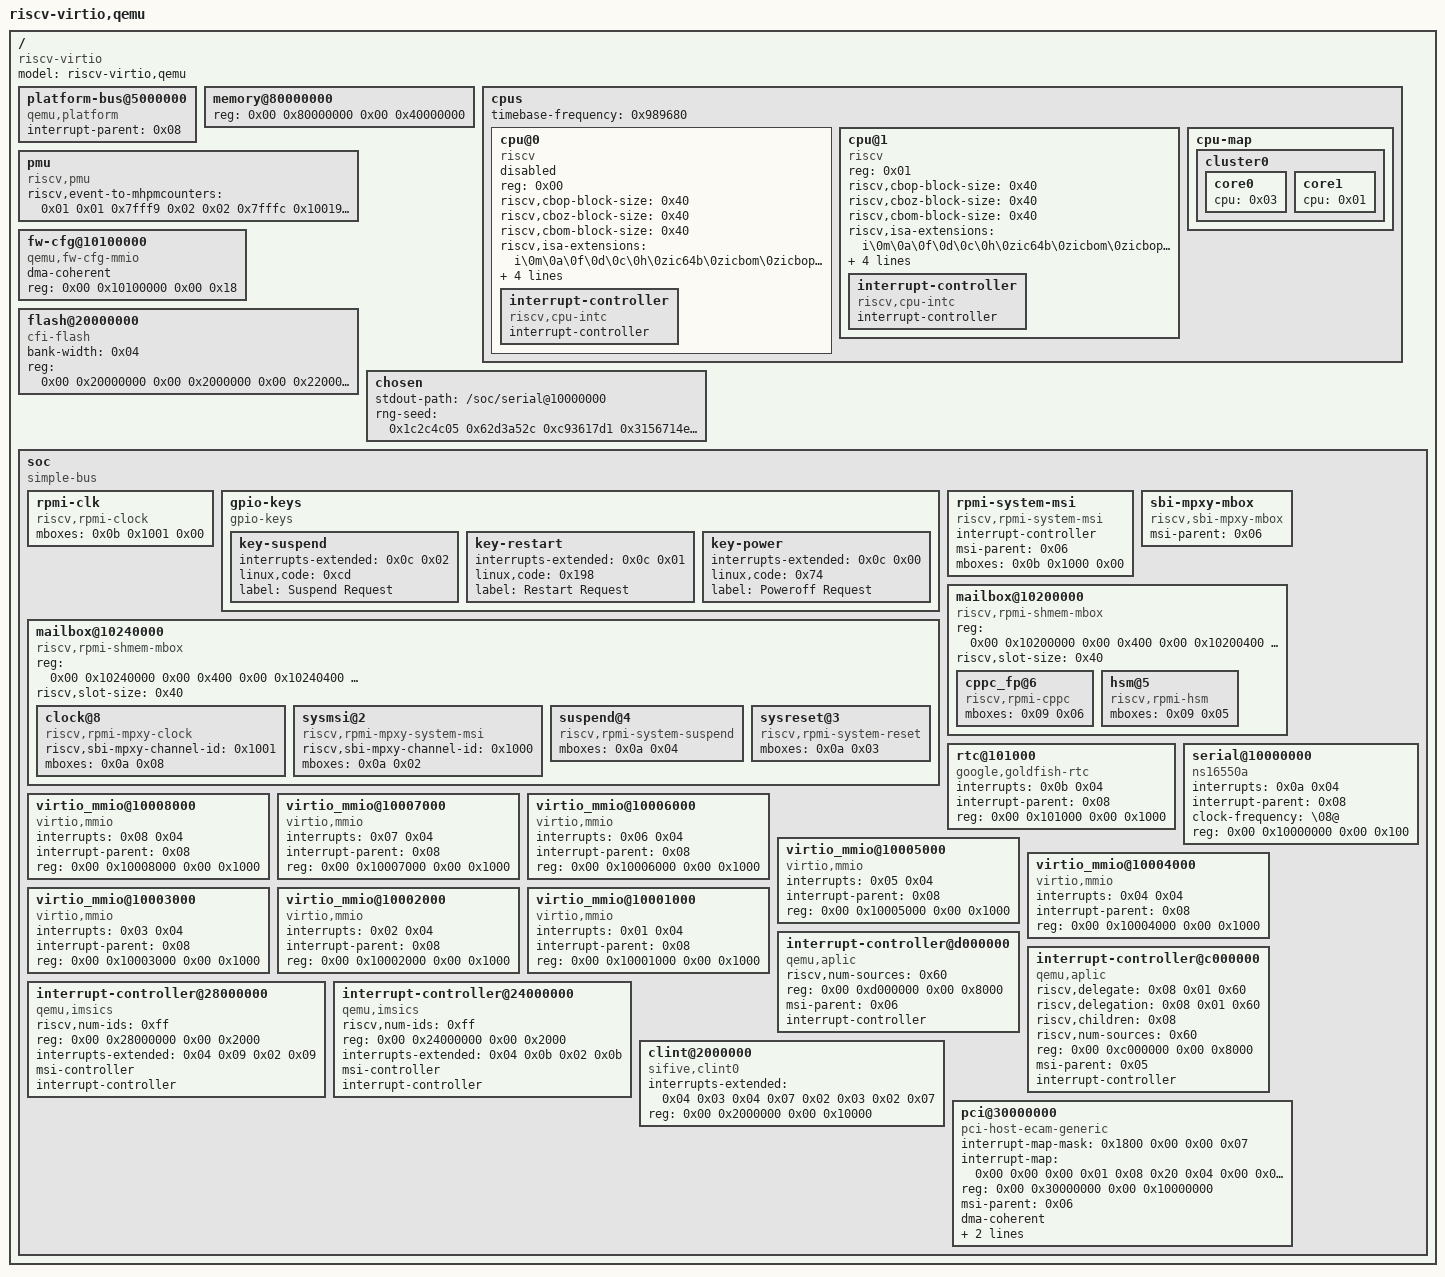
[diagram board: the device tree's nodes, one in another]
/dts-v1/;

/ {
	#address-cells = <0x02>;
	#size-cells = <0x02>;
	compatible = "riscv-virtio";
	model = "riscv-virtio,qemu";

	platform-bus@5000000 {
		interrupt-parent = <0x08>;
		ranges = <0x00 0x00 0x5000000 0x2000000>;
		#address-cells = <0x01>;
		#size-cells = <0x01>;
		compatible = "qemu,platform\0simple-bus";
	};

	memory@80000000 {
		device_type = "memory";
		reg = <0x00 0x80000000 0x00 0x40000000>;
	};

	cpus {
		#address-cells = <0x01>;
		#size-cells = <0x00>;
		timebase-frequency = <0x989680>;

		cpu@0 {
			phandle = <0x03>;
			device_type = "cpu";
			reg = <0x00>;
			status = "disabled";
			compatible = "riscv";
			riscv,cbop-block-size = <0x40>;
			riscv,cboz-block-size = <0x40>;
			riscv,cbom-block-size = <0x40>;
			riscv,isa-extensions = "i\0m\0a\0f\0d\0c\0h\0zic64b\0zicbom\0zicbop\0zicboz\0ziccamoa\0ziccif\0zicclsm\0ziccrse\0zicntr\0zicsr\0zifencei\0zihintntl\0zihintpause\0zihpm\0zmmul\0za64rs\0zaamo\0zalrsc\0zawrs\0zfa\0zca\0zcd\0zba\0zbb\0zbc\0zbs\0shcounterenw\0shgatpa\0shtvala\0shvsatpa\0shvstvala\0shvstvecd\0smaia\0ssaia\0ssccptr\0sscounterenw\0sstc\0sstvala\0sstvecd\0svadu\0svvptc";
			riscv,isa-base = "rv64i";
			riscv,isa = "rv64imafdch_zic64b_zicbom_zicbop_zicboz_ziccamoa_ziccif_zicclsm_ziccrse_zicntr_zicsr_zifencei_zihintntl_zihintpause_zihpm_zmmul_za64rs_zaamo_zalrsc_zawrs_zfa_zca_zcd_zba_zbb_zbc_zbs_shcounterenw_shgatpa_shtvala_shvsatpa_shvstvala_shvstvecd_smaia_ssaia_ssccptr_sscounterenw_sstc_sstvala_sstvecd_svadu_svvptc";
			mmu-type = "riscv,sv57";

			interrupt-controller {
				#interrupt-cells = <0x01>;
				interrupt-controller;
				compatible = "riscv,cpu-intc";
				phandle = <0x04>;
			};
		};

		cpu@1 {
			phandle = <0x01>;
			device_type = "cpu";
			reg = <0x01>;
			status = "okay";
			compatible = "riscv";
			riscv,cbop-block-size = <0x40>;
			riscv,cboz-block-size = <0x40>;
			riscv,cbom-block-size = <0x40>;
			riscv,isa-extensions = "i\0m\0a\0f\0d\0c\0h\0zic64b\0zicbom\0zicbop\0zicboz\0ziccamoa\0ziccif\0zicclsm\0ziccrse\0zicntr\0zicsr\0zifencei\0zihintntl\0zihintpause\0zihpm\0zmmul\0za64rs\0zaamo\0zalrsc\0zawrs\0zfa\0zca\0zcd\0zba\0zbb\0zbc\0zbs\0shcounterenw\0shgatpa\0shtvala\0shvsatpa\0shvstvala\0shvstvecd\0smaia\0ssaia\0ssccptr\0sscounterenw\0sstc\0sstvala\0sstvecd\0svadu\0svvptc";
			riscv,isa-base = "rv64i";
			riscv,isa = "rv64imafdch_zic64b_zicbom_zicbop_zicboz_ziccamoa_ziccif_zicclsm_ziccrse_zicntr_zicsr_zifencei_zihintntl_zihintpause_zihpm_zmmul_za64rs_zaamo_zalrsc_zawrs_zfa_zca_zcd_zba_zbb_zbc_zbs_shcounterenw_shgatpa_shtvala_shvsatpa_shvstvala_shvstvecd_smaia_ssaia_ssccptr_sscounterenw_sstc_sstvala_sstvecd_svadu_svvptc";
			mmu-type = "riscv,sv57";

			interrupt-controller {
				#interrupt-cells = <0x01>;
				interrupt-controller;
				compatible = "riscv,cpu-intc";
				phandle = <0x02>;
			};
		};

		cpu-map {

			cluster0 {

				core0 {
					cpu = <0x03>;
				};

				core1 {
					cpu = <0x01>;
				};
			};
		};
	};

	pmu {
		riscv,event-to-mhpmcounters = <0x01 0x01 0x7fff9 0x02 0x02 0x7fffc 0x10019 0x10019 0x7fff8 0x1001b 0x1001b 0x7fff8 0x10021 0x10021 0x7fff8>;
		compatible = "riscv,pmu";
	};

	fw-cfg@10100000 {
		dma-coherent;
		reg = <0x00 0x10100000 0x00 0x18>;
		compatible = "qemu,fw-cfg-mmio";
	};

	flash@20000000 {
		bank-width = <0x04>;
		reg = <0x00 0x20000000 0x00 0x2000000 0x00 0x22000000 0x00 0x2000000>;
		compatible = "cfi-flash";
	};

	chosen {
		stdout-path = "/soc/serial@10000000";
		rng-seed = <0x1c2c4c05 0x62d3a52c 0xc93617d1 0x3156714e 0x7f281c 0x8491b352 0xa7952257 0xecdf17e1>;
	};

	soc {
		#address-cells = <0x02>;
		#size-cells = <0x02>;
		compatible = "simple-bus";
		ranges;

		rpmi-clk {
			mboxes = <0x0b 0x1001 0x00>;
			#clock-cells = <0x01>;
			compatible = "riscv,rpmi-clock";
		};

		gpio-keys {
			compatible = "gpio-keys";

			key-suspend {
				interrupts-extended = <0x0c 0x02>;
				linux,code = <0xcd>;
				label = "Suspend Request";
			};

			key-restart {
				interrupts-extended = <0x0c 0x01>;
				linux,code = <0x198>;
				label = "Restart Request";
			};

			key-power {
				interrupts-extended = <0x0c 0x00>;
				linux,code = <0x74>;
				label = "Poweroff Request";
			};
		};

		rpmi-system-msi {
			phandle = <0x0c>;
			#interrupt-cells = <0x01>;
			interrupt-controller;
			msi-parent = <0x06>;
			mboxes = <0x0b 0x1000 0x00>;
			compatible = "riscv,rpmi-system-msi";
		};

		sbi-mpxy-mbox {
			phandle = <0x0b>;
			msi-parent = <0x06>;
			#mbox-cells = <0x02>;
			compatible = "riscv,sbi-mpxy-mbox";
		};

		mailbox@10240000 {
			compatible = "riscv,rpmi-shmem-mbox";
			phandle = <0x0a>;
			reg = <0x00 0x10240000 0x00 0x400 0x00 0x10240400 0x00 0x400 0x00 0x1024f000 0x00 0x1000>;
			reg-names = "a2p-req\0p2a-ack\0db-reg";
			#mbox-cells = <0x01>;
			riscv,slot-size = <0x40>;

			clock@8 {
				riscv,sbi-mpxy-channel-id = <0x1001>;
				mboxes = <0x0a 0x08>;
				compatible = "riscv,rpmi-mpxy-clock";
			};

			sysmsi@2 {
				riscv,sbi-mpxy-channel-id = <0x1000>;
				mboxes = <0x0a 0x02>;
				compatible = "riscv,rpmi-mpxy-system-msi";
			};

			suspend@4 {
				mboxes = <0x0a 0x04>;
				compatible = "riscv,rpmi-system-suspend";
			};

			sysreset@3 {
				mboxes = <0x0a 0x03>;
				compatible = "riscv,rpmi-system-reset";
			};
		};

		mailbox@10200000 {
			compatible = "riscv,rpmi-shmem-mbox";
			phandle = <0x09>;
			reg = <0x00 0x10200000 0x00 0x400 0x00 0x10200400 0x00 0x400 0x00 0x10230000 0x00 0x10000>;
			reg-names = "a2p-req\0p2a-ack\0db-reg";
			#mbox-cells = <0x01>;
			riscv,slot-size = <0x40>;

			cppc_fp@6 {
				mboxes = <0x09 0x06>;
				compatible = "riscv,rpmi-cppc";
			};

			hsm@5 {
				mboxes = <0x09 0x05>;
				compatible = "riscv,rpmi-hsm";
			};
		};

		rtc@101000 {
			interrupts = <0x0b 0x04>;
			interrupt-parent = <0x08>;
			reg = <0x00 0x101000 0x00 0x1000>;
			compatible = "google,goldfish-rtc";
		};

		serial@10000000 {
			interrupts = <0x0a 0x04>;
			interrupt-parent = <0x08>;
			clock-frequency = "\08@";
			reg = <0x00 0x10000000 0x00 0x100>;
			compatible = "ns16550a";
		};

		virtio_mmio@10008000 {
			interrupts = <0x08 0x04>;
			interrupt-parent = <0x08>;
			reg = <0x00 0x10008000 0x00 0x1000>;
			compatible = "virtio,mmio";
		};

		virtio_mmio@10007000 {
			interrupts = <0x07 0x04>;
			interrupt-parent = <0x08>;
			reg = <0x00 0x10007000 0x00 0x1000>;
			compatible = "virtio,mmio";
		};

		virtio_mmio@10006000 {
			interrupts = <0x06 0x04>;
			interrupt-parent = <0x08>;
			reg = <0x00 0x10006000 0x00 0x1000>;
			compatible = "virtio,mmio";
		};

		virtio_mmio@10005000 {
			interrupts = <0x05 0x04>;
			interrupt-parent = <0x08>;
			reg = <0x00 0x10005000 0x00 0x1000>;
			compatible = "virtio,mmio";
		};

		virtio_mmio@10004000 {
			interrupts = <0x04 0x04>;
			interrupt-parent = <0x08>;
			reg = <0x00 0x10004000 0x00 0x1000>;
			compatible = "virtio,mmio";
		};

		virtio_mmio@10003000 {
			interrupts = <0x03 0x04>;
			interrupt-parent = <0x08>;
			reg = <0x00 0x10003000 0x00 0x1000>;
			compatible = "virtio,mmio";
		};

		virtio_mmio@10002000 {
			interrupts = <0x02 0x04>;
			interrupt-parent = <0x08>;
			reg = <0x00 0x10002000 0x00 0x1000>;
			compatible = "virtio,mmio";
		};

		virtio_mmio@10001000 {
			interrupts = <0x01 0x04>;
			interrupt-parent = <0x08>;
			reg = <0x00 0x10001000 0x00 0x1000>;
			compatible = "virtio,mmio";
		};

		interrupt-controller@d000000 {
			phandle = <0x08>;
			riscv,num-sources = <0x60>;
			reg = <0x00 0xd000000 0x00 0x8000>;
			msi-parent = <0x06>;
			interrupt-controller;
			#interrupt-cells = <0x02>;
			#address-cells = <0x00>;
			compatible = "qemu,aplic\0riscv,aplic";
		};

		interrupt-controller@c000000 {
			phandle = <0x07>;
			riscv,delegate = <0x08 0x01 0x60>;
			riscv,delegation = <0x08 0x01 0x60>;
			riscv,children = <0x08>;
			riscv,num-sources = <0x60>;
			reg = <0x00 0xc000000 0x00 0x8000>;
			msi-parent = <0x05>;
			interrupt-controller;
			#interrupt-cells = <0x02>;
			#address-cells = <0x00>;
			compatible = "qemu,aplic\0riscv,aplic";
		};

		interrupt-controller@28000000 {
			phandle = <0x06>;
			riscv,num-ids = <0xff>;
			reg = <0x00 0x28000000 0x00 0x2000>;
			interrupts-extended = <0x04 0x09 0x02 0x09>;
			msi-controller;
			interrupt-controller;
			#interrupt-cells = <0x00>;
			compatible = "qemu,imsics\0riscv,imsics";
		};

		interrupt-controller@24000000 {
			phandle = <0x05>;
			riscv,num-ids = <0xff>;
			reg = <0x00 0x24000000 0x00 0x2000>;
			interrupts-extended = <0x04 0x0b 0x02 0x0b>;
			msi-controller;
			interrupt-controller;
			#interrupt-cells = <0x00>;
			compatible = "qemu,imsics\0riscv,imsics";
		};

		clint@2000000 {
			interrupts-extended = <0x04 0x03 0x04 0x07 0x02 0x03 0x02 0x07>;
			reg = <0x00 0x2000000 0x00 0x10000>;
			compatible = "sifive,clint0\0riscv,clint0";
		};

		pci@30000000 {
			interrupt-map-mask = <0x1800 0x00 0x00 0x07>;
			interrupt-map = <0x00 0x00 0x00 0x01 0x08 0x20 0x04 0x00 0x00 0x00 0x02 0x08 0x21 0x04 0x00 0x00 0x00 0x03 0x08 0x22 0x04 0x00 0x00 0x00 0x04 0x08 0x23 0x04 0x800 0x00 0x00 0x01 0x08 0x21 0x04 0x800 0x00 0x00 0x02 0x08 0x22 0x04 0x800 0x00 0x00 0x03 0x08 0x23 0x04 0x800 0x00 0x00 0x04 0x08 0x20 0x04 0x1000 0x00 0x00 0x01 0x08 0x22 0x04 0x1000 0x00 0x00 0x02 0x08 0x23 0x04 0x1000 0x00 0x00 0x03 0x08 0x20 0x04 0x1000 0x00 0x00 0x04 0x08 0x21 0x04 0x1800 0x00 0x00 0x01 0x08 0x23 0x04 0x1800 0x00 0x00 0x02 0x08 0x20 0x04 0x1800 0x00 0x00 0x03 0x08 0x21 0x04 0x1800 0x00 0x00 0x04 0x08 0x22 0x04>;
			ranges = <0x1000000 0x00 0x00 0x00 0x3000000 0x00 0x10000 0x2000000 0x00 0x40000000 0x00 0x40000000 0x00 0x40000000 0x3000000 0x04 0x00 0x04 0x00 0x04 0x00>;
			reg = <0x00 0x30000000 0x00 0x10000000>;
			msi-parent = <0x06>;
			dma-coherent;
			bus-range = <0x00 0xff>;
			linux,pci-domain = <0x00>;
			device_type = "pci";
			compatible = "pci-host-ecam-generic";
			#size-cells = <0x02>;
			#interrupt-cells = <0x01>;
			#address-cells = <0x03>;
		};
	};
};
